AUTOSAR XML (schema 4-0-3)
standard types defined: Boolean, UInt16
package /AUTOSAR_Platform/DataConstrs
  range DC_Boolean: raw 0..1
  range DC_UInt16: raw 0..65535
package /PATAC/MSM/ComponentTypes
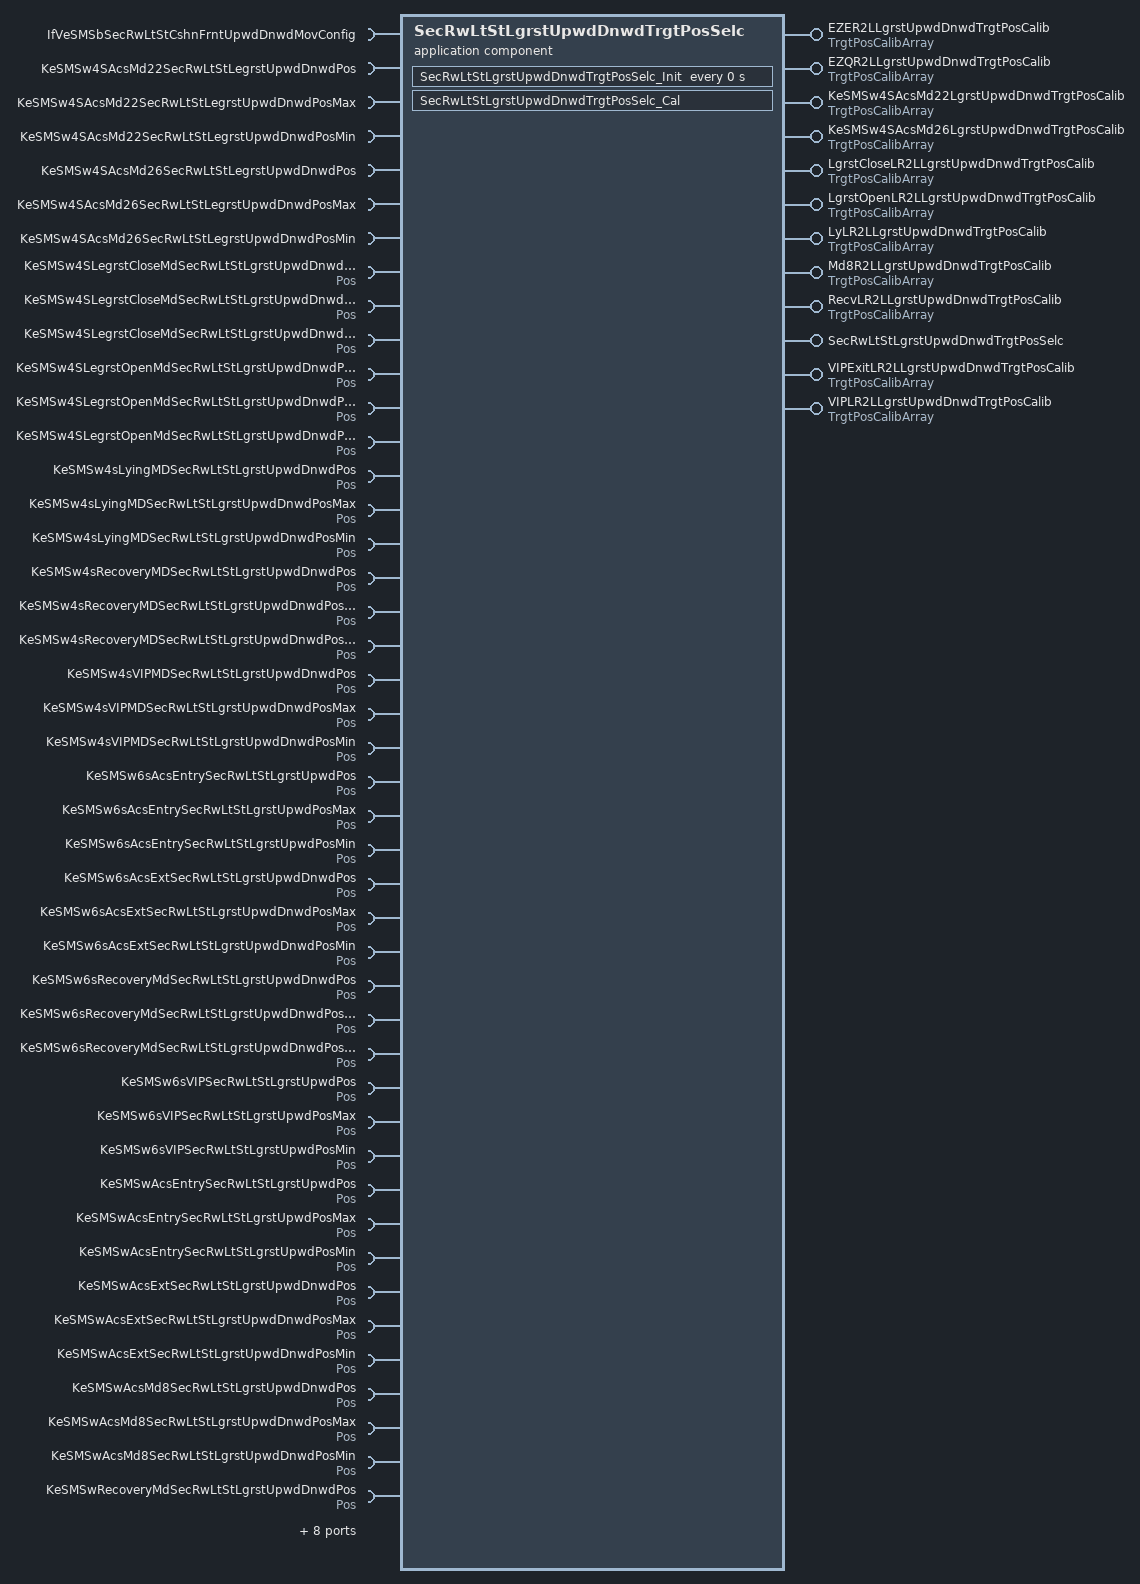
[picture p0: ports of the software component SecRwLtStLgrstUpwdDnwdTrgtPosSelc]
  application sw component type SecRwLtStLgrstUpwdDnwdTrgtPosSelc
    12 x provide port:
      EZER2LLgrstUpwdDnwdTrgtPosCalib: nonqueued-sender-com-spec{data-element=TrgtPosArray, init-value=[4095, 4095, 4095]}, provided-interface=TrgtPosCalibArray
      EZQR2LLgrstUpwdDnwdTrgtPosCalib: nonqueued-sender-com-spec{data-element=TrgtPosArray, init-value=[4095, 4095, 4095]}, provided-interface=TrgtPosCalibArray
      KeSMSw4SAcsMd22LgrstUpwdDnwdTrgtPosCalib: nonqueued-sender-com-spec{data-element=TrgtPosArray, init-value=[4095, 4095, 4095]}, provided-interface=TrgtPosCalibArray
      KeSMSw4SAcsMd26LgrstUpwdDnwdTrgtPosCalib: nonqueued-sender-com-spec{data-element=TrgtPosArray, init-value=[4095, 4095, 4095]}, provided-interface=TrgtPosCalibArray
      LgrstCloseLR2LLgrstUpwdDnwdTrgtPosCalib: nonqueued-sender-com-spec{data-element=TrgtPosArray, init-value=[4095, 4095, 4095]}, provided-interface=TrgtPosCalibArray
      LgrstOpenLR2LLgrstUpwdDnwdTrgtPosCalib: nonqueued-sender-com-spec{data-element=TrgtPosArray, init-value=[4095, 4095, 4095]}, provided-interface=TrgtPosCalibArray
      LyLR2LLgrstUpwdDnwdTrgtPosCalib: nonqueued-sender-com-spec{data-element=TrgtPosArray, init-value=[4095, 4095, 4095]}, provided-interface=TrgtPosCalibArray
      Md8R2LLgrstUpwdDnwdTrgtPosCalib: nonqueued-sender-com-spec{data-element=TrgtPosArray, init-value=[4095, 4095, 4095]}, provided-interface=TrgtPosCalibArray
      RecvLR2LLgrstUpwdDnwdTrgtPosCalib: nonqueued-sender-com-spec{data-element=TrgtPosArray, init-value=[4095, 4095, 4095]}, provided-interface=TrgtPosCalibArray
      SecRwLtStLgrstUpwdDnwdTrgtPosSelc: server-com-spec{operation=Cal, queue-length=1}, provided-interface=SecRwLtStLgrstUpwdDnwdTrgtPosSelc
      VIPExitLR2LLgrstUpwdDnwdTrgtPosCalib: nonqueued-sender-com-spec{data-element=TrgtPosArray, init-value=[4095, 4095, 4095]}, provided-interface=TrgtPosCalibArray
      VIPLR2LLgrstUpwdDnwdTrgtPosCalib: nonqueued-sender-com-spec{data-element=TrgtPosArray, init-value=[4095, 4095, 4095]}, provided-interface=TrgtPosCalibArray
    52 x require port:
      IfVeSMSbSecRwLtStCshnFrntUpwdDnwdMovConfig: nonqueued-receiver-com-spec{data-element=Val, filter=data-filter-type=ALWAYS, init-value=0}, required-interface=IfVeSMSbSecRwLtStCshnFrntUpwdDnwdMovConfig
      KeSMSw4SAcsMd22SecRwLtStLegrstUpwdDnwdPos: parameter-require-com-spec{init-value=0, parameter=KeSMSw4SAcsMd22SecRwLtStLegrstUpwdDnwdPos/Val}, required-interface=KeSMSw4SAcsMd22SecRwLtStLegrstUpwdDnwdPos
      KeSMSw4SAcsMd22SecRwLtStLegrstUpwdDnwdPosMax: parameter-require-com-spec{init-value=0, parameter=KeSMSw4SAcsMd22SecRwLtStLegrstUpwdDnwdPosMax/Val}, required-interface=KeSMSw4SAcsMd22SecRwLtStLegrstUpwdDnwdPosMax
      KeSMSw4SAcsMd22SecRwLtStLegrstUpwdDnwdPosMin: parameter-require-com-spec{init-value=0, parameter=KeSMSw4SAcsMd22SecRwLtStLegrstUpwdDnwdPosMin/Val}, required-interface=KeSMSw4SAcsMd22SecRwLtStLegrstUpwdDnwdPosMin
      KeSMSw4SAcsMd26SecRwLtStLegrstUpwdDnwdPos: parameter-require-com-spec{init-value=0, parameter=KeSMSw4SAcsMd26SecRwLtStLegrstUpwdDnwdPos/Val}, required-interface=KeSMSw4SAcsMd26SecRwLtStLegrstUpwdDnwdPos
      KeSMSw4SAcsMd26SecRwLtStLegrstUpwdDnwdPosMax: parameter-require-com-spec{init-value=0, parameter=KeSMSw4SAcsMd26SecRwLtStLegrstUpwdDnwdPosMax/Val}, required-interface=KeSMSw4SAcsMd26SecRwLtStLegrstUpwdDnwdPosMax
      KeSMSw4SAcsMd26SecRwLtStLegrstUpwdDnwdPosMin: parameter-require-com-spec{init-value=0, parameter=KeSMSw4SAcsMd26SecRwLtStLegrstUpwdDnwdPosMin/Val}, required-interface=KeSMSw4SAcsMd26SecRwLtStLegrstUpwdDnwdPosMin
      KeSMSw4SLegrstCloseMdSecRwLtStLgrstUpwdDnwdPos: parameter-require-com-spec{init-value=0, parameter=Pos/Val}, required-interface=Pos
      KeSMSw4SLegrstCloseMdSecRwLtStLgrstUpwdDnwdPosMax: parameter-require-com-spec{init-value=0, parameter=Pos/Val}, required-interface=Pos
      KeSMSw4SLegrstCloseMdSecRwLtStLgrstUpwdDnwdPosMin: parameter-require-com-spec{init-value=0, parameter=Pos/Val}, required-interface=Pos
      KeSMSw4SLegrstOpenMdSecRwLtStLgrstUpwdDnwdPos: parameter-require-com-spec{init-value=0, parameter=Pos/Val}, required-interface=Pos
      KeSMSw4SLegrstOpenMdSecRwLtStLgrstUpwdDnwdPosMax: parameter-require-com-spec{init-value=0, parameter=Pos/Val}, required-interface=Pos
      KeSMSw4SLegrstOpenMdSecRwLtStLgrstUpwdDnwdPosMin: parameter-require-com-spec{init-value=0, parameter=Pos/Val}, required-interface=Pos
      KeSMSw4sLyingMDSecRwLtStLgrstUpwdDnwdPos: parameter-require-com-spec{init-value=0, parameter=Pos/Val}, required-interface=Pos
      KeSMSw4sLyingMDSecRwLtStLgrstUpwdDnwdPosMax: parameter-require-com-spec{init-value=0, parameter=Pos/Val}, required-interface=Pos
      KeSMSw4sLyingMDSecRwLtStLgrstUpwdDnwdPosMin: parameter-require-com-spec{init-value=0, parameter=Pos/Val}, required-interface=Pos
      KeSMSw4sRecoveryMDSecRwLtStLgrstUpwdDnwdPos: parameter-require-com-spec{init-value=0, parameter=Pos/Val}, required-interface=Pos
      KeSMSw4sRecoveryMDSecRwLtStLgrstUpwdDnwdPosMax: parameter-require-com-spec{init-value=0, parameter=Pos/Val}, required-interface=Pos
      KeSMSw4sRecoveryMDSecRwLtStLgrstUpwdDnwdPosMin: parameter-require-com-spec{init-value=0, parameter=Pos/Val}, required-interface=Pos
      KeSMSw4sVIPMDSecRwLtStLgrstUpwdDnwdPos: parameter-require-com-spec{init-value=0, parameter=Pos/Val}, required-interface=Pos
      KeSMSw4sVIPMDSecRwLtStLgrstUpwdDnwdPosMax: parameter-require-com-spec{init-value=0, parameter=Pos/Val}, required-interface=Pos
      KeSMSw4sVIPMDSecRwLtStLgrstUpwdDnwdPosMin: parameter-require-com-spec{init-value=0, parameter=Pos/Val}, required-interface=Pos
      KeSMSw6sAcsEntrySecRwLtStLgrstUpwdPos: parameter-require-com-spec{init-value=4095, parameter=Pos/Val}, required-interface=Pos
      KeSMSw6sAcsEntrySecRwLtStLgrstUpwdPosMax: parameter-require-com-spec{init-value=40, parameter=Pos/Val}, required-interface=Pos
      KeSMSw6sAcsEntrySecRwLtStLgrstUpwdPosMin: parameter-require-com-spec{init-value=20, parameter=Pos/Val}, required-interface=Pos
      KeSMSw6sAcsExtSecRwLtStLgrstUpwdDnwdPos: parameter-require-com-spec{init-value=0, parameter=Pos/Val}, required-interface=Pos
      KeSMSw6sAcsExtSecRwLtStLgrstUpwdDnwdPosMax: parameter-require-com-spec{init-value=0, parameter=Pos/Val}, required-interface=Pos
      KeSMSw6sAcsExtSecRwLtStLgrstUpwdDnwdPosMin: parameter-require-com-spec{init-value=0, parameter=Pos/Val}, required-interface=Pos
      KeSMSw6sRecoveryMdSecRwLtStLgrstUpwdDnwdPos: parameter-require-com-spec{init-value=0, parameter=Pos/Val}, required-interface=Pos
      KeSMSw6sRecoveryMdSecRwLtStLgrstUpwdDnwdPosMax: parameter-require-com-spec{init-value=0, parameter=Pos/Val}, required-interface=Pos
      KeSMSw6sRecoveryMdSecRwLtStLgrstUpwdDnwdPosMin: parameter-require-com-spec{init-value=0, parameter=Pos/Val}, required-interface=Pos
      KeSMSw6sVIPSecRwLtStLgrstUpwdPos: parameter-require-com-spec{init-value=4000, parameter=Pos/Val}, required-interface=Pos
      KeSMSw6sVIPSecRwLtStLgrstUpwdPosMax: parameter-require-com-spec{init-value=4000, parameter=Pos/Val}, required-interface=Pos
      KeSMSw6sVIPSecRwLtStLgrstUpwdPosMin: parameter-require-com-spec{init-value=4000, parameter=Pos/Val}, required-interface=Pos
      KeSMSwAcsEntrySecRwLtStLgrstUpwdPos: parameter-require-com-spec{init-value=4095, parameter=Pos/Val}, required-interface=Pos
      KeSMSwAcsEntrySecRwLtStLgrstUpwdPosMax: parameter-require-com-spec{init-value=40, parameter=Pos/Val}, required-interface=Pos
      KeSMSwAcsEntrySecRwLtStLgrstUpwdPosMin: parameter-require-com-spec{init-value=20, parameter=Pos/Val}, required-interface=Pos
      KeSMSwAcsExtSecRwLtStLgrstUpwdDnwdPos: parameter-require-com-spec{init-value=0, parameter=Pos/Val}, required-interface=Pos
      KeSMSwAcsExtSecRwLtStLgrstUpwdDnwdPosMax: parameter-require-com-spec{init-value=0, parameter=Pos/Val}, required-interface=Pos
      KeSMSwAcsExtSecRwLtStLgrstUpwdDnwdPosMin: parameter-require-com-spec{init-value=0, parameter=Pos/Val}, required-interface=Pos
      KeSMSwAcsMd8SecRwLtStLgrstUpwdDnwdPos: parameter-require-com-spec{init-value=0, parameter=Pos/Val}, required-interface=Pos
      KeSMSwAcsMd8SecRwLtStLgrstUpwdDnwdPosMax: parameter-require-com-spec{init-value=0, parameter=Pos/Val}, required-interface=Pos
      KeSMSwAcsMd8SecRwLtStLgrstUpwdDnwdPosMin: parameter-require-com-spec{init-value=0, parameter=Pos/Val}, required-interface=Pos
      KeSMSwRecoveryMdSecRwLtStLgrstUpwdDnwdPos: parameter-require-com-spec{init-value=0, parameter=Pos/Val}, required-interface=Pos
      KeSMSwRecoveryMdSecRwLtStLgrstUpwdDnwdPosMax: parameter-require-com-spec{init-value=0, parameter=Pos/Val}, required-interface=Pos
      KeSMSwRecoveryMdSecRwLtStLgrstUpwdDnwdPosMin: parameter-require-com-spec{init-value=0, parameter=Pos/Val}, required-interface=Pos
      KeSMSwVIPSecRwLtStLgrstUpwdPos: parameter-require-com-spec{init-value=4000, parameter=Pos/Val}, required-interface=Pos
      KeSMSwVIPSecRwLtStLgrstUpwdPosMax: parameter-require-com-spec{init-value=4000, parameter=Pos/Val}, required-interface=Pos
      KeSMSwVIPSecRwLtStLgrstUpwdPosMin: parameter-require-com-spec{init-value=4000, parameter=Pos/Val}, required-interface=Pos
      StNumFlg: required-interface=StNumFlg
        required-com-specs:
          data-element=Is4s, filter=data-filter-type=ALWAYS, init-value=0
          data-element=Is6s, filter=data-filter-type=ALWAYS, init-value=0
          data-element=Is6s7s, filter=data-filter-type=ALWAYS, init-value=0
          data-element=Is7s, filter=data-filter-type=ALWAYS, init-value=0
      VIPL557TrgtPos: required-com-specs=[VIPL557TrgtPos/Get, VIPL557TrgtPos/Set], required-interface=VIPL557TrgtPos
      VIPLExit557TrgtPos: required-com-specs=[VIPLExit557TrgtPos/Get, VIPLExit557TrgtPos/Set], required-interface=VIPLExit557TrgtPos
    behavior SecRwLtStLgrstUpwdDnwdTrgtPosSelc_InternalBehavior
      operation invoked event OIT_SecRwLtStLgrstUpwdDnwdTrgtPosSelc_Cal_SecRwLtStLgrstUpwdDnwdTrgtPosSelc_Cal: start-on-event=SecRwLtStLgrstUpwdDnwdTrgtPosSelc_Cal, operation=SecRwLtStLgrstUpwdDnwdTrgtPosSelc.Cal
      timing event SecRwLtStLgrstUpwdDnwdTrgtPosSelc_InitEvent: start-on-event=SecRwLtStLgrstUpwdDnwdTrgtPosSelc_Init, period=0
      runnable SecRwLtStLgrstUpwdDnwdTrgtPosSelc_Cal
        data-receive-point-by-arguments:
          5 x access:
            REC_IfVeSMSbSecRwLtStCshnFrntUpwdDnwdMovConfig_Val: accessed-variable=IfVeSMSbSecRwLtStCshnFrntUpwdDnwdMovConfig.Val
            REC_StNumFlg_Is4s: accessed-variable=StNumFlg.Is4s
            REC_StNumFlg_Is6s: accessed-variable=StNumFlg.Is6s
            REC_StNumFlg_Is6s7s: accessed-variable=StNumFlg.Is6s7s
            REC_StNumFlg_Is7s: accessed-variable=StNumFlg.Is7s
        data-send-points:
          11 x access:
            SEND_EZER2LLgrstUpwdDnwdTrgtPosCalib_TrgtPosArray: accessed-variable=EZER2LLgrstUpwdDnwdTrgtPosCalib.TrgtPosArray
            SEND_EZQR2LLgrstUpwdDnwdTrgtPosCalib_TrgtPosArray: accessed-variable=EZQR2LLgrstUpwdDnwdTrgtPosCalib.TrgtPosArray
            SEND_KeSMSw4SAcsMd22LgrstUpwdDnwdTrgtPosCalib_TrgtPosArray: accessed-variable=KeSMSw4SAcsMd22LgrstUpwdDnwdTrgtPosCalib.TrgtPosArray
            SEND_KeSMSw4SAcsMd26LgrstUpwdDnwdTrgtPosCalib_TrgtPosArray: accessed-variable=KeSMSw4SAcsMd26LgrstUpwdDnwdTrgtPosCalib.TrgtPosArray
            SEND_LgrstCloseLR2LLgrstUpwdDnwdTrgtPosCalib_TrgtPosArray: accessed-variable=LgrstCloseLR2LLgrstUpwdDnwdTrgtPosCalib.TrgtPosArray
            SEND_LgrstOpenLR2LLgrstUpwdDnwdTrgtPosCalib_TrgtPosArray: accessed-variable=LgrstOpenLR2LLgrstUpwdDnwdTrgtPosCalib.TrgtPosArray
            SEND_LyLR2LLgrstUpwdDnwdTrgtPosCalib_TrgtPosArray: accessed-variable=LyLR2LLgrstUpwdDnwdTrgtPosCalib.TrgtPosArray
            SEND_Md8R2LLgrstUpwdDnwdTrgtPosCalib_TrgtPosArray: accessed-variable=Md8R2LLgrstUpwdDnwdTrgtPosCalib.TrgtPosArray
            SEND_RecvLR2LLgrstUpwdDnwdTrgtPosCalib_TrgtPosArray: accessed-variable=RecvLR2LLgrstUpwdDnwdTrgtPosCalib.TrgtPosArray
            SEND_VIPExitLR2LLgrstUpwdDnwdTrgtPosCalib_TrgtPosArray: accessed-variable=VIPExitLR2LLgrstUpwdDnwdTrgtPosCalib.TrgtPosArray
            SEND_VIPLR2LLgrstUpwdDnwdTrgtPosCalib_TrgtPosArray: accessed-variable=VIPLR2LLgrstUpwdDnwdTrgtPosCalib.TrgtPosArray
        48 x parameter access:
          PA_KeSMSw4SAcsMd22SecRwLtStLegrstUpwdDnwdPos_Val: accessed-parameter=KeSMSw4SAcsMd22SecRwLtStLegrstUpwdDnwdPos.Val
          PA_KeSMSw4SAcsMd22SecRwLtStLegrstUpwdDnwdPosMax_Val: accessed-parameter=KeSMSw4SAcsMd22SecRwLtStLegrstUpwdDnwdPosMax.Val
          PA_KeSMSw4SAcsMd22SecRwLtStLegrstUpwdDnwdPosMin_Val: accessed-parameter=KeSMSw4SAcsMd22SecRwLtStLegrstUpwdDnwdPosMin.Val
          PA_KeSMSw4SAcsMd26SecRwLtStLegrstUpwdDnwdPos_Val: accessed-parameter=KeSMSw4SAcsMd26SecRwLtStLegrstUpwdDnwdPos.Val
          PA_KeSMSw4SAcsMd26SecRwLtStLegrstUpwdDnwdPosMax_Val: accessed-parameter=KeSMSw4SAcsMd26SecRwLtStLegrstUpwdDnwdPosMax.Val
          PA_KeSMSw4SAcsMd26SecRwLtStLegrstUpwdDnwdPosMin_Val: accessed-parameter=KeSMSw4SAcsMd26SecRwLtStLegrstUpwdDnwdPosMin.Val
          PA_KeSMSw4SLegrstCloseMdSecRwLtStLgrstUpwdDnwdPos_Val: accessed-parameter=KeSMSw4SLegrstCloseMdSecRwLtStLgrstUpwdDnwdPos.Val
          PA_KeSMSw4SLegrstCloseMdSecRwLtStLgrstUpwdDnwdPosMax_Val: accessed-parameter=KeSMSw4SLegrstCloseMdSecRwLtStLgrstUpwdDnwdPosMax.Val
          PA_KeSMSw4SLegrstCloseMdSecRwLtStLgrstUpwdDnwdPosMin_Val: accessed-parameter=KeSMSw4SLegrstCloseMdSecRwLtStLgrstUpwdDnwdPosMin.Val
          PA_KeSMSw4SLegrstOpenMdSecRwLtStLgrstUpwdDnwdPos_Val: accessed-parameter=KeSMSw4SLegrstOpenMdSecRwLtStLgrstUpwdDnwdPos.Val
          PA_KeSMSw4SLegrstOpenMdSecRwLtStLgrstUpwdDnwdPosMax_Val: accessed-parameter=KeSMSw4SLegrstOpenMdSecRwLtStLgrstUpwdDnwdPosMax.Val
          PA_KeSMSw4SLegrstOpenMdSecRwLtStLgrstUpwdDnwdPosMin_Val: accessed-parameter=KeSMSw4SLegrstOpenMdSecRwLtStLgrstUpwdDnwdPosMin.Val
          PA_KeSMSw4sLyingMDSecRwLtStLgrstUpwdDnwdPos_Val: accessed-parameter=KeSMSw4sLyingMDSecRwLtStLgrstUpwdDnwdPos.Val
          PA_KeSMSw4sLyingMDSecRwLtStLgrstUpwdDnwdPosMax_Val: accessed-parameter=KeSMSw4sLyingMDSecRwLtStLgrstUpwdDnwdPosMax.Val
          PA_KeSMSw4sLyingMDSecRwLtStLgrstUpwdDnwdPosMin_Val: accessed-parameter=KeSMSw4sLyingMDSecRwLtStLgrstUpwdDnwdPosMin.Val
          PA_KeSMSw4sRecoveryMDSecRwLtStLgrstUpwdDnwdPos_Val: accessed-parameter=KeSMSw4sRecoveryMDSecRwLtStLgrstUpwdDnwdPos.Val
          PA_KeSMSw4sRecoveryMDSecRwLtStLgrstUpwdDnwdPosMax_Val: accessed-parameter=KeSMSw4sRecoveryMDSecRwLtStLgrstUpwdDnwdPosMax.Val
          PA_KeSMSw4sRecoveryMDSecRwLtStLgrstUpwdDnwdPosMin_Val: accessed-parameter=KeSMSw4sRecoveryMDSecRwLtStLgrstUpwdDnwdPosMin.Val
          PA_KeSMSw4sVIPMDSecRwLtStLgrstUpwdDnwdPos_Val: accessed-parameter=KeSMSw4sVIPMDSecRwLtStLgrstUpwdDnwdPos.Val
          PA_KeSMSw4sVIPMDSecRwLtStLgrstUpwdDnwdPosMax_Val: accessed-parameter=KeSMSw4sVIPMDSecRwLtStLgrstUpwdDnwdPosMax.Val
          PA_KeSMSw4sVIPMDSecRwLtStLgrstUpwdDnwdPosMin_Val: accessed-parameter=KeSMSw4sVIPMDSecRwLtStLgrstUpwdDnwdPosMin.Val
          PA_KeSMSw6sAcsEntrySecRwLtStLgrstUpwdPos_Val: accessed-parameter=KeSMSw6sAcsEntrySecRwLtStLgrstUpwdPos.Val
          PA_KeSMSw6sAcsEntrySecRwLtStLgrstUpwdPosMax_Val: accessed-parameter=KeSMSw6sAcsEntrySecRwLtStLgrstUpwdPosMax.Val
          PA_KeSMSw6sAcsEntrySecRwLtStLgrstUpwdPosMin_Val: accessed-parameter=KeSMSw6sAcsEntrySecRwLtStLgrstUpwdPosMin.Val
          PA_KeSMSw6sAcsExtSecRwLtStLgrstUpwdDnwdPos_Val: accessed-parameter=KeSMSw6sAcsExtSecRwLtStLgrstUpwdDnwdPos.Val
          PA_KeSMSw6sAcsExtSecRwLtStLgrstUpwdDnwdPosMax_Val: accessed-parameter=KeSMSw6sAcsExtSecRwLtStLgrstUpwdDnwdPosMax.Val
          PA_KeSMSw6sAcsExtSecRwLtStLgrstUpwdDnwdPosMin_Val: accessed-parameter=KeSMSw6sAcsExtSecRwLtStLgrstUpwdDnwdPosMin.Val
          PA_KeSMSw6sRecoveryMdSecRwLtStLgrstUpwdDnwdPos_Val: accessed-parameter=KeSMSw6sRecoveryMdSecRwLtStLgrstUpwdDnwdPos.Val
          PA_KeSMSw6sRecoveryMdSecRwLtStLgrstUpwdDnwdPosMax_Val: accessed-parameter=KeSMSw6sRecoveryMdSecRwLtStLgrstUpwdDnwdPosMax.Val
          PA_KeSMSw6sRecoveryMdSecRwLtStLgrstUpwdDnwdPosMin_Val: accessed-parameter=KeSMSw6sRecoveryMdSecRwLtStLgrstUpwdDnwdPosMin.Val
          PA_KeSMSw6sVIPSecRwLtStLgrstUpwdPos_Val: accessed-parameter=KeSMSw6sVIPSecRwLtStLgrstUpwdPos.Val
          PA_KeSMSw6sVIPSecRwLtStLgrstUpwdPosMax_Val: accessed-parameter=KeSMSw6sVIPSecRwLtStLgrstUpwdPosMax.Val
          PA_KeSMSw6sVIPSecRwLtStLgrstUpwdPosMin_Val: accessed-parameter=KeSMSw6sVIPSecRwLtStLgrstUpwdPosMin.Val
          PA_KeSMSwAcsEntrySecRwLtStLgrstUpwdPos_Val: accessed-parameter=KeSMSwAcsEntrySecRwLtStLgrstUpwdPos.Val
          PA_KeSMSwAcsEntrySecRwLtStLgrstUpwdPosMax_Val: accessed-parameter=KeSMSwAcsEntrySecRwLtStLgrstUpwdPosMax.Val
          PA_KeSMSwAcsEntrySecRwLtStLgrstUpwdPosMin_Val: accessed-parameter=KeSMSwAcsEntrySecRwLtStLgrstUpwdPosMin.Val
          PA_KeSMSwAcsExtSecRwLtStLgrstUpwdDnwdPos_Val: accessed-parameter=KeSMSwAcsExtSecRwLtStLgrstUpwdDnwdPos.Val
          PA_KeSMSwAcsExtSecRwLtStLgrstUpwdDnwdPosMax_Val: accessed-parameter=KeSMSwAcsExtSecRwLtStLgrstUpwdDnwdPosMax.Val
          PA_KeSMSwAcsExtSecRwLtStLgrstUpwdDnwdPosMin_Val: accessed-parameter=KeSMSwAcsExtSecRwLtStLgrstUpwdDnwdPosMin.Val
          PA_KeSMSwAcsMd8SecRwLtStLgrstUpwdDnwdPos_Val: accessed-parameter=KeSMSwAcsMd8SecRwLtStLgrstUpwdDnwdPos.Val
          PA_KeSMSwAcsMd8SecRwLtStLgrstUpwdDnwdPosMax_Val: accessed-parameter=KeSMSwAcsMd8SecRwLtStLgrstUpwdDnwdPosMax.Val
          PA_KeSMSwAcsMd8SecRwLtStLgrstUpwdDnwdPosMin_Val: accessed-parameter=KeSMSwAcsMd8SecRwLtStLgrstUpwdDnwdPosMin.Val
          PA_KeSMSwRecoveryMdSecRwLtStLgrstUpwdDnwdPos_Val: accessed-parameter=KeSMSwRecoveryMdSecRwLtStLgrstUpwdDnwdPos.Val
          PA_KeSMSwRecoveryMdSecRwLtStLgrstUpwdDnwdPosMax_Val: accessed-parameter=KeSMSwRecoveryMdSecRwLtStLgrstUpwdDnwdPosMax.Val
          PA_KeSMSwRecoveryMdSecRwLtStLgrstUpwdDnwdPosMin_Val: accessed-parameter=KeSMSwRecoveryMdSecRwLtStLgrstUpwdDnwdPosMin.Val
          PA_KeSMSwVIPSecRwLtStLgrstUpwdPos_Val: accessed-parameter=KeSMSwVIPSecRwLtStLgrstUpwdPos.Val
          PA_KeSMSwVIPSecRwLtStLgrstUpwdPosMax_Val: accessed-parameter=KeSMSwVIPSecRwLtStLgrstUpwdPosMax.Val
          PA_KeSMSwVIPSecRwLtStLgrstUpwdPosMin_Val: accessed-parameter=KeSMSwVIPSecRwLtStLgrstUpwdPosMin.Val
        sync call SC_VIPL557TrgtPos_Get: operation=VIPL557TrgtPos.Get, timeout=0
        sync call SC_VIPLExit557TrgtPos_Get: operation=VIPLExit557TrgtPos.Get, timeout=0
      runnable SecRwLtStLgrstUpwdDnwdTrgtPosSelc_Init
        48 x parameter access:
          PA_KeSMSw4SAcsMd22SecRwLtStLegrstUpwdDnwdPos_Val: accessed-parameter=KeSMSw4SAcsMd22SecRwLtStLegrstUpwdDnwdPos.Val
          PA_KeSMSw4SAcsMd22SecRwLtStLegrstUpwdDnwdPosMax_Val: accessed-parameter=KeSMSw4SAcsMd22SecRwLtStLegrstUpwdDnwdPosMax.Val
          PA_KeSMSw4SAcsMd22SecRwLtStLegrstUpwdDnwdPosMin_Val: accessed-parameter=KeSMSw4SAcsMd22SecRwLtStLegrstUpwdDnwdPosMin.Val
          PA_KeSMSw4SAcsMd26SecRwLtStLegrstUpwdDnwdPos_Val: accessed-parameter=KeSMSw4SAcsMd26SecRwLtStLegrstUpwdDnwdPos.Val
          PA_KeSMSw4SAcsMd26SecRwLtStLegrstUpwdDnwdPosMax_Val: accessed-parameter=KeSMSw4SAcsMd26SecRwLtStLegrstUpwdDnwdPosMax.Val
          PA_KeSMSw4SAcsMd26SecRwLtStLegrstUpwdDnwdPosMin_Val: accessed-parameter=KeSMSw4SAcsMd26SecRwLtStLegrstUpwdDnwdPosMin.Val
          PA_KeSMSw4SLegrstCloseMdSecRwLtStLgrstUpwdDnwdPos_Val: accessed-parameter=KeSMSw4SLegrstCloseMdSecRwLtStLgrstUpwdDnwdPos.Val
          PA_KeSMSw4SLegrstCloseMdSecRwLtStLgrstUpwdDnwdPosMax_Val: accessed-parameter=KeSMSw4SLegrstCloseMdSecRwLtStLgrstUpwdDnwdPosMax.Val
          PA_KeSMSw4SLegrstCloseMdSecRwLtStLgrstUpwdDnwdPosMin_Val: accessed-parameter=KeSMSw4SLegrstCloseMdSecRwLtStLgrstUpwdDnwdPosMin.Val
          PA_KeSMSw4SLegrstOpenMdSecRwLtStLgrstUpwdDnwdPos_Val: accessed-parameter=KeSMSw4SLegrstOpenMdSecRwLtStLgrstUpwdDnwdPos.Val
          PA_KeSMSw4SLegrstOpenMdSecRwLtStLgrstUpwdDnwdPosMax_Val: accessed-parameter=KeSMSw4SLegrstOpenMdSecRwLtStLgrstUpwdDnwdPosMax.Val
          PA_KeSMSw4SLegrstOpenMdSecRwLtStLgrstUpwdDnwdPosMin_Val: accessed-parameter=KeSMSw4SLegrstOpenMdSecRwLtStLgrstUpwdDnwdPosMin.Val
          PA_KeSMSw4sLyingMDSecRwLtStLgrstUpwdDnwdPos_Val: accessed-parameter=KeSMSw4sLyingMDSecRwLtStLgrstUpwdDnwdPos.Val
          PA_KeSMSw4sLyingMDSecRwLtStLgrstUpwdDnwdPosMax_Val: accessed-parameter=KeSMSw4sLyingMDSecRwLtStLgrstUpwdDnwdPosMax.Val
          PA_KeSMSw4sLyingMDSecRwLtStLgrstUpwdDnwdPosMin_Val: accessed-parameter=KeSMSw4sLyingMDSecRwLtStLgrstUpwdDnwdPosMin.Val
          PA_KeSMSw4sRecoveryMDSecRwLtStLgrstUpwdDnwdPos_Val: accessed-parameter=KeSMSw4sRecoveryMDSecRwLtStLgrstUpwdDnwdPos.Val
          PA_KeSMSw4sRecoveryMDSecRwLtStLgrstUpwdDnwdPosMax_Val: accessed-parameter=KeSMSw4sRecoveryMDSecRwLtStLgrstUpwdDnwdPosMax.Val
          PA_KeSMSw4sRecoveryMDSecRwLtStLgrstUpwdDnwdPosMin_Val: accessed-parameter=KeSMSw4sRecoveryMDSecRwLtStLgrstUpwdDnwdPosMin.Val
          PA_KeSMSw4sVIPMDSecRwLtStLgrstUpwdDnwdPos_Val: accessed-parameter=KeSMSw4sVIPMDSecRwLtStLgrstUpwdDnwdPos.Val
          PA_KeSMSw4sVIPMDSecRwLtStLgrstUpwdDnwdPosMax_Val: accessed-parameter=KeSMSw4sVIPMDSecRwLtStLgrstUpwdDnwdPosMax.Val
          PA_KeSMSw4sVIPMDSecRwLtStLgrstUpwdDnwdPosMin_Val: accessed-parameter=KeSMSw4sVIPMDSecRwLtStLgrstUpwdDnwdPosMin.Val
          PA_KeSMSw6sAcsEntrySecRwLtStLgrstUpwdPos_Val: accessed-parameter=KeSMSw6sAcsEntrySecRwLtStLgrstUpwdPos.Val
          PA_KeSMSw6sAcsEntrySecRwLtStLgrstUpwdPosMax_Val: accessed-parameter=KeSMSw6sAcsEntrySecRwLtStLgrstUpwdPosMax.Val
          PA_KeSMSw6sAcsEntrySecRwLtStLgrstUpwdPosMin_Val: accessed-parameter=KeSMSw6sAcsEntrySecRwLtStLgrstUpwdPosMin.Val
          PA_KeSMSw6sAcsExtSecRwLtStLgrstUpwdDnwdPos_Val: accessed-parameter=KeSMSw6sAcsExtSecRwLtStLgrstUpwdDnwdPos.Val
          PA_KeSMSw6sAcsExtSecRwLtStLgrstUpwdDnwdPosMax_Val: accessed-parameter=KeSMSw6sAcsExtSecRwLtStLgrstUpwdDnwdPosMax.Val
          PA_KeSMSw6sAcsExtSecRwLtStLgrstUpwdDnwdPosMin_Val: accessed-parameter=KeSMSw6sAcsExtSecRwLtStLgrstUpwdDnwdPosMin.Val
          PA_KeSMSw6sRecoveryMdSecRwLtStLgrstUpwdDnwdPos_Val: accessed-parameter=KeSMSw6sRecoveryMdSecRwLtStLgrstUpwdDnwdPos.Val
          PA_KeSMSw6sRecoveryMdSecRwLtStLgrstUpwdDnwdPosMax_Val: accessed-parameter=KeSMSw6sRecoveryMdSecRwLtStLgrstUpwdDnwdPosMax.Val
          PA_KeSMSw6sRecoveryMdSecRwLtStLgrstUpwdDnwdPosMin_Val: accessed-parameter=KeSMSw6sRecoveryMdSecRwLtStLgrstUpwdDnwdPosMin.Val
          PA_KeSMSw6sVIPSecRwLtStLgrstUpwdPos_Val: accessed-parameter=KeSMSw6sVIPSecRwLtStLgrstUpwdPos.Val
          PA_KeSMSw6sVIPSecRwLtStLgrstUpwdPosMax_Val: accessed-parameter=KeSMSw6sVIPSecRwLtStLgrstUpwdPosMax.Val
          PA_KeSMSw6sVIPSecRwLtStLgrstUpwdPosMin_Val: accessed-parameter=KeSMSw6sVIPSecRwLtStLgrstUpwdPosMin.Val
          PA_KeSMSwAcsEntrySecRwLtStLgrstUpwdPos_Val: accessed-parameter=KeSMSwAcsEntrySecRwLtStLgrstUpwdPos.Val
          PA_KeSMSwAcsEntrySecRwLtStLgrstUpwdPosMax_Val: accessed-parameter=KeSMSwAcsEntrySecRwLtStLgrstUpwdPosMax.Val
          PA_KeSMSwAcsEntrySecRwLtStLgrstUpwdPosMin_Val: accessed-parameter=KeSMSwAcsEntrySecRwLtStLgrstUpwdPosMin.Val
          PA_KeSMSwAcsExtSecRwLtStLgrstUpwdDnwdPos_Val: accessed-parameter=KeSMSwAcsExtSecRwLtStLgrstUpwdDnwdPos.Val
          PA_KeSMSwAcsExtSecRwLtStLgrstUpwdDnwdPosMax_Val: accessed-parameter=KeSMSwAcsExtSecRwLtStLgrstUpwdDnwdPosMax.Val
          PA_KeSMSwAcsExtSecRwLtStLgrstUpwdDnwdPosMin_Val: accessed-parameter=KeSMSwAcsExtSecRwLtStLgrstUpwdDnwdPosMin.Val
          PA_KeSMSwAcsMd8SecRwLtStLgrstUpwdDnwdPos_Val: accessed-parameter=KeSMSwAcsMd8SecRwLtStLgrstUpwdDnwdPos.Val
          PA_KeSMSwAcsMd8SecRwLtStLgrstUpwdDnwdPosMax_Val: accessed-parameter=KeSMSwAcsMd8SecRwLtStLgrstUpwdDnwdPosMax.Val
          PA_KeSMSwAcsMd8SecRwLtStLgrstUpwdDnwdPosMin_Val: accessed-parameter=KeSMSwAcsMd8SecRwLtStLgrstUpwdDnwdPosMin.Val
          PA_KeSMSwRecoveryMdSecRwLtStLgrstUpwdDnwdPos_Val: accessed-parameter=KeSMSwRecoveryMdSecRwLtStLgrstUpwdDnwdPos.Val
          PA_KeSMSwRecoveryMdSecRwLtStLgrstUpwdDnwdPosMax_Val: accessed-parameter=KeSMSwRecoveryMdSecRwLtStLgrstUpwdDnwdPosMax.Val
          PA_KeSMSwRecoveryMdSecRwLtStLgrstUpwdDnwdPosMin_Val: accessed-parameter=KeSMSwRecoveryMdSecRwLtStLgrstUpwdDnwdPosMin.Val
          PA_KeSMSwVIPSecRwLtStLgrstUpwdPos_Val: accessed-parameter=KeSMSwVIPSecRwLtStLgrstUpwdPos.Val
          PA_KeSMSwVIPSecRwLtStLgrstUpwdPosMax_Val: accessed-parameter=KeSMSwVIPSecRwLtStLgrstUpwdPosMax.Val
          PA_KeSMSwVIPSecRwLtStLgrstUpwdPosMin_Val: accessed-parameter=KeSMSwVIPSecRwLtStLgrstUpwdPosMin.Val
  swc implementation SecRwLtStLgrstUpwdDnwdTrgtPosSelc_Implementation: behavior=SecRwLtStLgrstUpwdDnwdTrgtPosSelc_InternalBehavior
    code-descriptors:
      code Default: artifact-descriptors=autosar-engineering-object={short-label=Default, category=SWSRC}
package /PATAC/MSM/ModeAdjust/CalPortInterface
  7 x parameter interface:
    KeSMSw4SAcsMd22SecRwLtStLegrstUpwdDnwdPos
      parameter data prototype Val: sw-calibration-access=READ-WRITE, type=UInt16
    KeSMSw4SAcsMd22SecRwLtStLegrstUpwdDnwdPosMax
      parameter data prototype Val: sw-calibration-access=READ-WRITE, type=UInt16
    KeSMSw4SAcsMd22SecRwLtStLegrstUpwdDnwdPosMin
      parameter data prototype Val: sw-calibration-access=READ-WRITE, type=UInt16
    KeSMSw4SAcsMd26SecRwLtStLegrstUpwdDnwdPos
      parameter data prototype Val: sw-calibration-access=READ-WRITE, type=UInt16
    KeSMSw4SAcsMd26SecRwLtStLegrstUpwdDnwdPosMax
      parameter data prototype Val: sw-calibration-access=READ-WRITE, type=UInt16
    KeSMSw4SAcsMd26SecRwLtStLegrstUpwdDnwdPosMin
      parameter data prototype Val: sw-calibration-access=READ-WRITE, type=UInt16
    Pos
      parameter data prototype Val: sw-calibration-access=READ-WRITE, type=UInt16
package /PATAC/MSM/ModeAdjust/DataType
  impl type TrgtPosCalibArray: category=ARRAY, sw-calibration-access=READ-ONLY, type-emitter=RTE  # 0:pos 1:max 2:min
    element Element: array-size=3, array-size-semantics=FIXED-SIZE, implementation-data-type=UInt16, invalid-value=0
package /PATAC/MSM/ModeAdjust/PortInterface
  client server interface SecRwLtStLgrstUpwdDnwdTrgtPosSelc
    operation Cal
  client server interface VIPL557TrgtPos
    operation Get
      5 x arg, all with type=UInt16, direction=OUT, server-argument-impl-policy=USE-ARGUMENT-TYPE:
        SecRwLtStBkReclnTrgtPos
        SecRwLtStZeroTrgtPos
        SecRwLtStLgrstUpwdDnwdTrgtPos
        SecRwLtStLgrstInwdOtwdTrgtPos
        SecRwLtStFwdBkwdTrgtPos
    operation Set
      5 x arg, all with type=UInt16, direction=IN, server-argument-impl-policy=USE-ARGUMENT-TYPE:
        SecRwLtStBkReclnTrgtPos
        SecRwLtStZeroTrgtPos
        SecRwLtStLgrstUpwdDnwdTrgtPos
        SecRwLtStLgrstInwdOtwdTrgtPos
        SecRwLtStFwdBkwdTrgtPos
  client server interface VIPLExit557TrgtPos
    operation Get
      7 x arg, all with type=UInt16, direction=OUT, server-argument-impl-policy=USE-ARGUMENT-TYPE:
        SecRwLtStBkReclnTrgtPos
        SecRwLtStZeroTrgtPos
        SecRwLtStLgrstUpwdDnwdTrgtPos
        SecRwLtStLgrstInwdOtwdTrgtPos
        ThdRwLtStBkReclnTrgtPos
        ThdRwLtStFwdBkwdTrgtPos
        SecRwLtStFwdBkwdTrgtPos
    operation Set
  sender receiver interface StNumFlg
    4 x data, all with type=Boolean:
      Is4s
      Is6s
      Is6s7s
      Is7s
    invalidation-policys:
      data-element=Is4s, handle-invalid=DONT-INVALIDATE
      data-element=Is6s, handle-invalid=DONT-INVALIDATE
      data-element=Is6s7s, handle-invalid=DONT-INVALIDATE
      data-element=Is7s, handle-invalid=DONT-INVALIDATE
  sender receiver interface TrgtPosCalibArray: invalidation-policy{data-element=TrgtPosArray, handle-invalid=DONT-INVALIDATE}
    data TrgtPosArray: type=TrgtPosCalibArray  # 0:Pos 1:Max 2:Min
package /PATAC/MSM/PortInterfaces
  sender receiver interface IfVeSMSbSecRwLtStCshnFrntUpwdDnwdMovConfig: invalidation-policy{data-element=Val, handle-invalid=DONT-INVALIDATE}
    data Val: type=Boolean
